AUTOSAR XML (schema 00052)
package /apd/AdaptiveApplicationSwComponentTypes
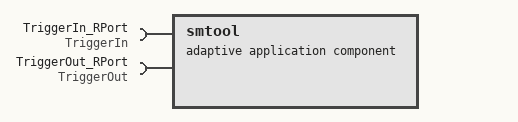
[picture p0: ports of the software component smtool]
  adaptive application sw component type smtool
    require port TriggerIn_RPort: required-interface=TriggerIn
    require port TriggerOut_RPort: required-interface=TriggerOut
package /apd/Executables
  executable smtool: category=APPLICATION_LEVEL, minimum-timer-granularity=1000
    root sw component prototype smtool: application-type=smtool
